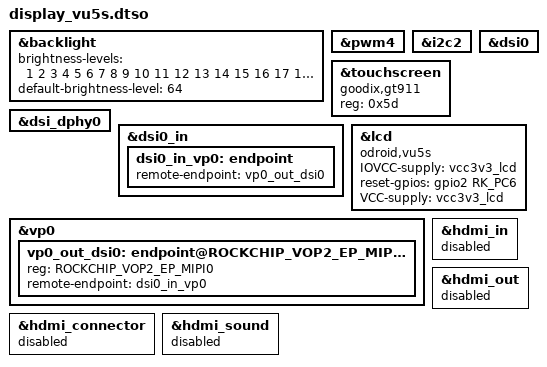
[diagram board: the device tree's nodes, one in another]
/dts-v1/;
/plugin/;

#include <dt-bindings/gpio/gpio.h>
#include <dt-bindings/pinctrl/rockchip.h>
#include <dt-bindings/soc/rockchip,vop2.h>

&backlight {
	brightness-levels = <
		1   2   3   4   5   6   7   8
		9   10  11  12  13  14  15  16
		17  18  19  20  21  22  23  24
		25  26  27  28  29  30  31  32
		33  34  35  36  37  38  39  40
		41  42  43  44  45  46  47  48
		49  50  51  52  53  54  55  56
		57  58  59  60  61  62  63  64
		65  66  67  68  69  70  71  72
		73  74  75  76  77  78  79  80
		81  82  83  84  85  86  87  88
		89  90  91  92  93  94  95  96
		97  98  99  100 101 102 103 104
		105 106 107 108 109 110 111 112
		113 114 115 116 117 118 119 120
		121 122 123 124 125 126 127 128
		>;
	default-brightness-level = <64>;
	status = "okay";
};

&pwm4 {
	status = "okay";
};

&i2c2 {
	status = "okay";
};

&touchscreen {
	compatible = "goodix,gt911";
	reg = <0x5d>;
	status = "okay";
};

&dsi_dphy0 {
	status = "okay";
};

&dsi0 {
	status = "okay";
};

&dsi0_in {
	dsi0_in_vp0: endpoint {
		remote-endpoint = <&vp0_out_dsi0>;
	};
};

&lcd {
	compatible = "odroid,vu5s";
	IOVCC-supply = <&vcc3v3_lcd>;
	reset-gpios = <&gpio2 RK_PC6 GPIO_ACTIVE_HIGH>;
	status = "okay";
	VCC-supply = <&vcc3v3_lcd>;
};

&vp0 {
	vp0_out_dsi0: endpoint@ROCKCHIP_VOP2_EP_MIPI0 {
		reg = <ROCKCHIP_VOP2_EP_MIPI0>;
		remote-endpoint = <&dsi0_in_vp0>;
	};
};

/*
&hdmi {
	status = "disabled";
};
*/

&hdmi_connector {
	status = "disabled";
};

&hdmi_in {
	status = "disabled";
};

&hdmi_out {
	status = "disabled";
};

&hdmi_sound {
	status = "disabled";
};
